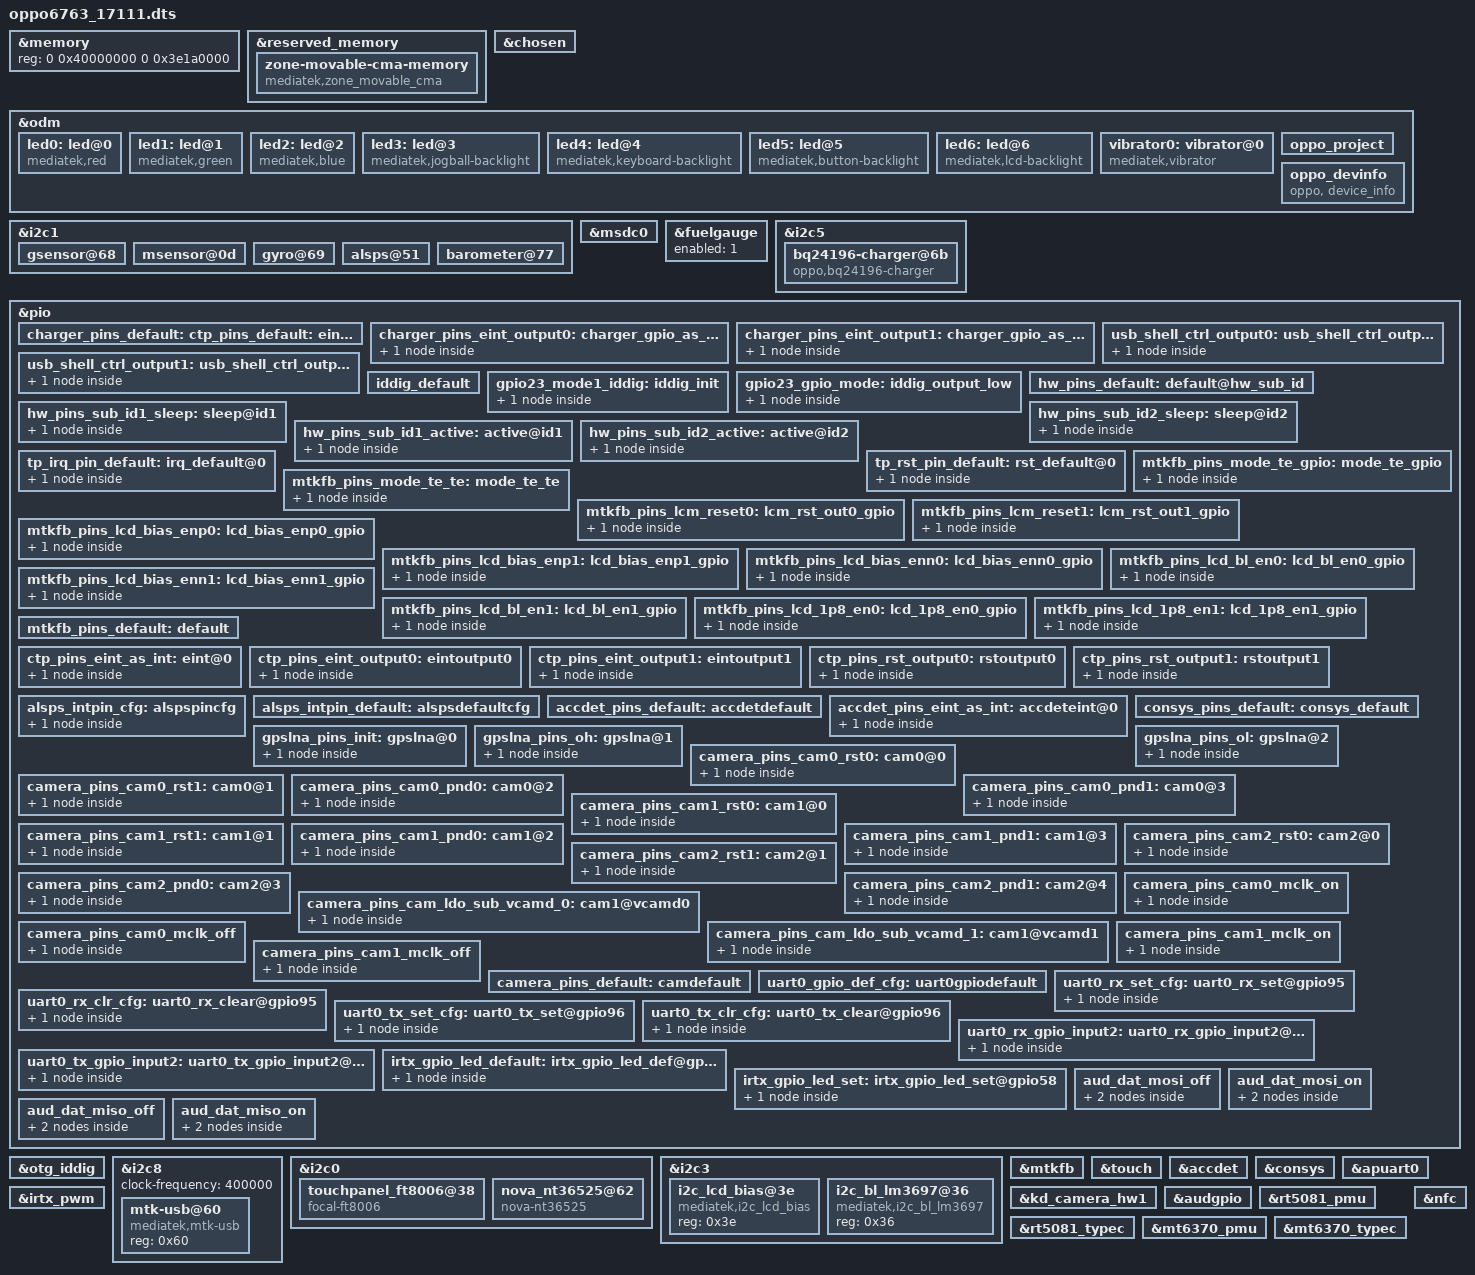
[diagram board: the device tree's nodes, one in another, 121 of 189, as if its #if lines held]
#include <generated/autoconf.h>
/dts-v1/;

#ifdef CONFIG_MTK_DTBO_FEATURE
/plugin/;
#include <dt-bindings/interrupt-controller/irq.h>
#include <dt-bindings/interrupt-controller/arm-gic.h>
#include <dt-bindings/mmc/mt6763-msdc.h>
#include <dt-bindings/pinctrl/mt6763-pinfunc.h>
#else
#include "mt6763.dts"
#endif


&memory {
		device_type = "memory";
		reg = <0 0x40000000 0 0x3e1a0000>;
};

&reserved_memory {
		#address-cells = <2>;
		#size-cells = <2>;
		ranges;

		zone-movable-cma-memory {
			compatible = "mediatek,zone_movable_cma";
			size = <0 0xffc00000>;
			alignment = <0 0x10000000>;
			alloc-ranges = <0 0xc0000000 1 0x00000000>;
	};
};


/* chosen */
&chosen {
		bootargs = "console=tty0 console=ttyMT0,921600n1 root=/dev/ram initrd=0x45000000,\
0x1000000 loglevel=8 androidboot.selinux=permissive androidboot.hardware=mt6763 initcall_debug=1 maxcpus=1";
		/* fpga may has no lk, we need to specify display info here */
		/* fb buffer is reserved using this dts by memory node above */
		atag,videolfb-fb_base_h = <0x0>;
		atag,videolfb-fb_base_l = <0x5e605000>;
		atag,videolfb-islcmfound = <1>;
		/* because no lk, so lcm is not inited */
		atag,videolfb-islcm_inited = <0>;
		atag,videolfb-fps= <6000>;
		atag,videolfb-vramSize= <0x017bb000>;
		atag,videolfb-lcmname= "nt35695B_fhd_dsi_cmd_auo_rt5081_drv";
};

&odm {
	led0:led@0 {
		compatible = "mediatek,red";
		led_mode = <0>;
		data = <1>;
		pwm_config = <0 0 0 0 0>;
	};
	led1:led@1 {
		compatible = "mediatek,green";
		led_mode = <0>;
		data = <1>;
		pwm_config = <0 0 0 0 0>;
	};
	led2:led@2 {
		compatible = "mediatek,blue";
		led_mode = <0>;
		data = <1>;
		pwm_config = <0 0 0 0 0>;
	};
	led3:led@3 {
		compatible = "mediatek,jogball-backlight";
		led_mode = <0>;
		data = <1>;
		pwm_config = <0 0 0 0 0>;
	};
	led4:led@4 {
		compatible = "mediatek,keyboard-backlight";
		led_mode = <0>;
		data = <1>;
		pwm_config = <0 0 0 0 0>;
	};
	led5:led@5 {
		compatible = "mediatek,button-backlight";
		led_mode = <0>;
		data = <1>;
		pwm_config = <0 0 0 0 0>;
	};
	led6:led@6 {
		compatible = "mediatek,lcd-backlight";
		/* #ifndef VENDOR_EDIT */
		/* LiPing-m@PSW.MM.Display.LCD.Machine, 2017/11/03, Add for porting 17331 lcd driver */
		/* led_mode = <5>; */
		/* #else VENDOR_EDIT */
		led_mode = <4>;
		/* #endif VENDOR_EDIT */
		data = <1>;
		pwm_config = <0 3 0 0 0>;
	};
	vibrator0:vibrator@0 {
		compatible = "mediatek,vibrator";
		vib_timer = <25>;
		vib_limit = <9>;
		vib_vol= <9>;
	};
    //#ifdef VENDOR_EDIT
	/*Bin.Li@EXP.BSP.bootloader.bootflow, 2017/05/15, Add for oppo project */
	oppo_project:oppo_project {
		nProject = <0>;
		nModem = <0>;
		nOperator = <0>;
		nPCBVersion = <0>;
	};
	//#endif /*VENDOR_EDIT*/
    //ifdef VENDOR_EDIT
	/* Bin.Li@EXP.BSP.bootloader.bootflow, 2017/07/07, Add device-info */
	oppo_devinfo:oppo_devinfo {
			compatible = "oppo, device_info";
		};
	//endif
};

&i2c1 {
/*  start sensor */
	gsensor@68 {
		i2c_num	= <1>;
		direction = <4>;
		power_id = <0xffff>;
		power_vol = <0>;
		firlen = <16>;
		is_batch_supported = <1>;
	};

	msensor@0d {
		i2c_num = <1>;
		i2c_addr = <0x0d 0 0 0>;
		direction = <8>;
		power_id = <0xffff>;
		power_vol = <0>;
		is_batch_supported = <0>;
	};

	gyro@69 {
		i2c_num = <1>;
		i2c_addr = <0x69 0 0 0>;
		direction = <4>;
		power_id = <0xffff>;
		power_vol = <0>;
		firlen = <0>;
		is_batch_supported = <0>;
	};

	alsps@51 {
		pinctrl-names = "pin_default", "pin_cfg";
		pinctrl-0 = <&alsps_intpin_default>;
		pinctrl-1 = <&alsps_intpin_cfg>;
		status = "okay";
		/* customization */
		i2c_num = <1>;
		i2c_addr = <0x51 0 0 0>;
		polling_mode_ps = <0>;
		polling_mode_als = <1>;
		power_id = <0xffff>;
		power_vol = <0>;
		als_level = <0 328 861 1377 3125 7721 7767 12621 23062 28430 33274 47116 57694 57694 65535>;
		als_value = <0 133 304 502 1004 2005 3058 5005 8008 10010 12000 16000 20000 20000 20000 20000>;
		ps_threshold_high = <26>;
		ps_threshold_low = <21>;
		is_batch_supported_ps = <0>;
		is_batch_supported_als = <0>;
	};

	barometer@77 {
		i2c_num = <1>;
		i2c_addr = <0x77 0 0 0>;
		direction = <0>;
		power_id = <0xffff>;
		power_vol = <0>;
		firlen = <32>;
		is_batch_supported = <0>;
	};
/* end sensor */
};

&msdc0 {
	status = "okay";
};
//#ifdef VENDOR_EDIT
//PengNan@BSP.CHG.Basic, 2017/09/07, add for compatabling two fuelgauge.
&fuelgauge{
	enabled = <1>;
};
//#endif
//#ifdef VENDOR_EDIT
/* ChaoYing.Chen@EXP.BSP.CHG.basic, 2017/05/31, Add for charge driver */
&i2c5 {
	bq24196-charger@6b {
		status = "okay";
		compatible = "oppo,bq24196-charger";
		reg = <0x6b 0>;
		pinctrl-names = "default", "charger_gpio_as_output_low", "charger_gpio_as_output_high", "usb_shell_ctrl_output_low", "usb_shell_ctrl_output_high";
		pinctrl-0 = <&charger_pins_default>;
		pinctrl-1 = <&charger_pins_eint_output0>;
		pinctrl-2 = <&charger_pins_eint_output1>;
		pinctrl-3 = <&usb_shell_ctrl_output0>;
		pinctrl-4 = <&usb_shell_ctrl_output1>;
		qcom,input_current_charger_ma = <2000>;
		qcom,input_current_usb_ma = <500>;
		qcom,input_current_led_ma = <900>;
		qcom,input_current_led_ma_forcmcc = <500>;
		qcom,input_current_camera_ma = <1200>;

		qcom,input_current_calling_ma = <1500>;
		qcom,iterm-disabled = <0>;
		qcom,iterm-ma = <150>;
		qcom,recharge-mv = <100>;
		qcom,external_gauge;
		qcom,batt_capacity_mah = <3090>;
		qcom,removed_bat_decidegc = <190>;  /* < -19C */
		qcom,cold_bat_decidegc = <30>;  /* -3C ~ 0C */
		qcom,temp_cold_vfloat_mv = <3980>;
		qcom,temp_cold_fastchg_current_ma = <364>;
		qcom,little_cold_bat_decidegc = <0>;	/* 0C ~ 5C */
		qcom,temp_little_cold_vfloat_mv = <4370>;
		qcom,temp_little_cold_fastchg_current_ma = <435>;
		qcom,cool_bat_decidegc = <50>;	/* 5C ~ 12C */
		qcom,temp_cool_vfloat_mv = <4370>;
		qcom,temp_cool_fastchg_current_ma_high = <725>;
		qcom,temp_cool_fastchg_current_ma_low = <435>;
		qcom,little_cool_bat_decidegc = <120>;	/* 12C ~ 22C */
		qcom,temp_little_cool_vfloat_mv = <4370>;
		qcom,temp_little_cool_fastchg_current_ma = <1380>;
		qcom,normal_bat_decidegc = <220>;	/* 22C ~ 45C */
		qcom,temp_normal_fastchg_current_ma = <2024>;
		qcom,temp_normal_vfloat_mv_normalchg = <4370>;
		qcom,temp_normal_vfloat_mv_voocchg = <4370>;
		qcom,warm_bat_decidegc = <450>;		/* 45C ~ 53C */
		qcom,temp_warm_vfloat_mv = <4080>;
		qcom,temp_warm_fastchg_current_ma = <725>;
		qcom,hot_bat_decidegc = <530>;
		qcom,non_standard_vfloat_mv = <4000>;
		qcom,non_standard_fastchg_current_ma = <512>;
		qcom,non_standard_vfloat_sw_limit = <3950>;
		qcom,cold_vfloat_sw_limit = <3930>;
		qcom,little_cold_vfloat_sw_limit = <4320>;
		qcom,cool_vfloat_sw_limit = <4320>;
		qcom,little_cool_vfloat_sw_limit = <4320>;
		qcom,normal_vfloat_sw_limit = <4320>;
		qcom,warm_vfloat_sw_limit = <4030>;

		qcom,non_standard_vfloat_over_sw_limit = <3980>;
		qcom,cold_vfloat_over_sw_limit = <3980>;
		qcom,little_cold_vfloat_over_sw_limit = <4390>;
		qcom,cool_vfloat_over_sw_limit = <4390>;
		qcom,little_cool_vfloat_over_sw_limit = <4390>;
		qcom,normal_vfloat_over_sw_limit = <4390>;
		qcom,warm_vfloat_over_sw_limit = <4080>;
		qcom,sw_vfloat_over_protect_enable;

		qcom,max_chg_time_sec = <36000>;
		qcom,charger_hv_thr = <5800>;
		qcom,charger_lv_thr = <3400>;
		qcom,vbatt_full_thr = <4400>;
		qcom,vbatt_hv_thr = <4500>;
		qcom,vfloat_step_mv = <16>;
	//	qcom,suspend_after_full;
		qcom,check_batt_full_by_sw;
		qcom,chg_ctrl_by_calling;
		qcom,chg_ctrl_by_lcd;
		qcom,chg_ctrl_by_camera;
		qcom,usb_shell_ctrl;
		qcom,usb_switch_gpio 		= <&pio 3 0x00>;
		qcom,usb_shell_ctrl_gpio 			= <&pio 21 0x00>;
	};
};

&pio {
	charger_pins_default: eint0default {
	};
	charger_pins_eint_output0: charger_gpio_as_output_low {
		pins_cmd_dat {
			pins = <PINMUX_GPIO3__FUNC_GPIO3>;
			slew-rate = <1>;
			output-low;
		};
	};
	charger_pins_eint_output1: charger_gpio_as_output_high {
		pins_cmd_dat {
			pins = <PINMUX_GPIO3__FUNC_GPIO3>;
			slew-rate = <1>;
			output-high;
		};
	};
	usb_shell_ctrl_output0: usb_shell_ctrl_output_low {
		pins_cmd_dat {
			pins = <PINMUX_GPIO21__FUNC_GPIO21>;
			slew-rate = <1>;
			output-low;	
		};
	};
	usb_shell_ctrl_output1: usb_shell_ctrl_output_high {
		pins_cmd_dat {
			pins = <PINMUX_GPIO21__FUNC_GPIO21>;
			slew-rate = <1>;
			output-high;	
		};
	};
};
&otg_iddig {
	/* Qiao.Hu@EXP.BSP.CHG.basic, 2017/05/09, Add for otg support */
	pinctrl-names = "iddig_default", "iddig_init", "iddig_output_low" ;
	pinctrl-0 = <&iddig_default>;
	pinctrl-1 = <&gpio23_mode1_iddig>;
	pinctrl-2 = <&gpio23_gpio_mode>;
	status = "okay";
    	/* Qiao.Hu@EXP.BSP.CHG.basic, 2017/05/25, Add for OTG GPIO */
	qcom,otg_switch_gpio = <23>;

};
&pio {
	iddig_default: iddig_default {
	};

	gpio23_mode1_iddig: iddig_init {
		pins_cmd_dat {
			pins = <PINMUX_GPIO23__FUNC_IDDIG>;
			slew-rate = <0>;
			bias-pull-up = <00>;
		};
	};
	gpio23_gpio_mode: iddig_output_low {
		pins_cmd_dat {
			pins = <PINMUX_GPIO23__FUNC_GPIO23>;
			slew-rate = <1>;
			output-low;
		};
	};

};
//#endif /* VENDOR_EDIT */

//ifdef VENDOR_EDIT
/* Bin.Li@EXP.BSP.bootloader.bootflow, 2017/07/07, Add device-info */
&oppo_devinfo {
	Hw,sub_hwid_1 = <&pio 10 0x00>;
	Hw,sub_hwid_2 = <&pio 58 0x00>;
	pinctrl-names = "default", "hw_sub_id_sleep", "hw_sub_id_active";
	pinctrl-0 = <&hw_pins_sub_id1_active &hw_pins_sub_id2_active>;
	pinctrl-1 = <&hw_pins_sub_id1_sleep &hw_pins_sub_id2_sleep>;
	pinctrl-2 = <&hw_pins_sub_id1_active &hw_pins_sub_id2_active>;
};

&pio {
	hw_pins_default:default@hw_sub_id {
	};

	hw_pins_sub_id1_sleep:sleep@id1 {
			pins_cmd_dat {
			pins = <PINMUX_GPIO10__FUNC_GPIO10>;
			slew-rate = <0>;
			bias-pull-down = <00>;
			input-enable;
			};
	};

	hw_pins_sub_id2_sleep:sleep@id2 {
			pins_cmd_dat {
			pins = <PINMUX_GPIO58__FUNC_GPIO58>;
			bias-pull-down = <00>;
			input-enable;
			};
	};

	hw_pins_sub_id1_active:active@id1 {
		pins_cmd_dat {
		pins = <PINMUX_GPIO10__FUNC_GPIO10>;
			slew-rate = <0>;
			bias-pull-up = <00>;
			input-enable;
			};
	};
	hw_pins_sub_id2_active:active@id2 {
		pins_cmd_dat {
		pins = <PINMUX_GPIO58__FUNC_GPIO58>;
			slew-rate = <0>;
			bias-pull-up = <00>;
			input-enable;
			};
	};
};
//endif

&i2c8 {
	#address-cells = <1>;
	#size-cells = <0>;
	clock-frequency = <400000>;

	mtk-usb@60 {
		compatible = "mediatek,mtk-usb";
		reg = <0x60>;
		status = "okay";
	};
};

//#ifdef VENDOR_EDIT
/* ZhongWenjie@PSW.BSP.TP,  2018/05/07, Add for TP ft8006*/
&i2c0 {
    touchpanel_ft8006@38 {
        compatible = "focal-ft8006";
        reg = <0x38>;
        status = "okay";
        chip-name = "FT8006";

        interrupt-parent = <&eintc>;
        interrupts = <1 0x2002>;

        irq-gpio = <&pio 1 0x2002>;
        reset-gpio = <&pio 7 0>;

        pinctrl-names = "default";
        pinctrl-0 = <&tp_irq_pin_default &tp_rst_pin_default>;

        touchpanel,max-num-support = <10>;
        touchpanel,tx-rx-num = <18 32>;
        touchpanel,panel-coords = <720 1440>;
        touchpanel,display-coords = <720 1440>;

        incell_screen;
        edge_limit_support;
        charger_pump_support;
        black_gesture_support;
        esd_handle_support;
        //spurious_fingerprint_support;
        //lcd_trigger_fp_check;
        black_gesture_test_support;

        /*
        *Virtual Key Config:
        *1:touchpanel,button-type: <virtualkey_type  supportted_button-map>
        *virtualkey_type:
        *Type 1: using board_properties
        *Type 2: using same IC (button zone&& touch zone are seprate)
        *Type 3: using diffrent IC (button zone&& touch zone are seprate)
        *Type 4: No need of virtual key process
        *supportted_button-map:select|menu|home|back
        *
        *2:touchpanel,button-map
        *type (X1,Y1)(X2,Y2)(X3,Y3)(Width_X,Hight_Y)--Only when button-type is 0
        */

        touchpanel,button-type = <4 0x00>;
    };

    nova_nt36525@62 {
        compatible = "nova-nt36525";
        reg = <0x62>;
        status = "okay";
        chip-name = "NT36525";

        interrupt-parent = <&eintc>;
        interrupts = <1 0x2001>;
        irq-gpio = <&pio 1 0x2001>;

        pinctrl-names = "default";
        pinctrl-0 = <&tp_irq_pin_default &tp_rst_pin_default>;

        touchpanel,max-num-support = <10>;
        touchpanel,tx-rx-num = <18 32>;
        touchpanel,panel-coords = <720 1440>;
        touchpanel,display-coords = <720 1440>;

        incell_screen;
        edge_limit_support;
        black_gesture_support;
        charger_pump_support;
        esd_handle_support;
        //spurious_fingerprint_support;
        //lcd_trigger_fp_check;
        black_gesture_test_support;

        /*
        *Virtual Key Config:
        *1:touchpanel,button-type: <virtualkey_type  supportted_button-map>
        *virtualkey_type:
        *Type 1: using board_properties
        *Type 2: using same IC (button zone&& touch zone are seprate)
        *Type 3: using diffrent IC (button zone&& touch zone are seprate)
        *Type 4: No need of virtual key process
        *supportted_button-map:select|menu|home|back
        *
        *2:touchpanel,button-map
        *type (X1,Y1)(X2,Y2)(X3,Y3)(Width_X,Hight_Y)--Only when button-type is 0
        */

        touchpanel,button-type = <2 0x05>;
    };
};

&pio {
    tp_irq_pin_default:irq_default@0 {
        pins_cmd_dat {
            pins = <PINMUX_GPIO1__FUNC_GPIO1>;
            slew-rate = <0>;
            bias-pull-up;
            input-enable;
        };
    };

    tp_rst_pin_default:rst_default@0 {
        pins_cmd_dat {
            pins = <PINMUX_GPIO7__FUNC_GPIO7>;
            slew-rate = <1>;
            bias-disable;
        };
    };
};
//#endif /* VENDOR_EDIT */

/* #ifdef VENDOR_EDIT */
/* LiPing-m@PSW.MM.Display.LCD.Machine, 2017/11/03, Add for porting 17331 lcd driver */
&i2c3 {
    #address-cells = <1>;
    #size-cells = <0>;

       i2c_lcd_bias@3e {
               compatible = "mediatek,i2c_lcd_bias";
               reg = <0x3e>;
               status = "okay";
       };
       i2c_bl_lm3697@36 {
               compatible = "mediatek,i2c_bl_lm3697";
               reg = <0x36>;
               status = "okay";
       };
};

&pio {

	mtkfb_pins_mode_te_gpio: mode_te_gpio {
		pins_cmd_dat {
			pins = <PINMUX_GPIO44__FUNC_GPIO44>;
	};
		};

	mtkfb_pins_mode_te_te: mode_te_te {
		pins_cmd_dat {
			pins = <PINMUX_GPIO44__FUNC_DSI_TE>;
		};
};

	mtkfb_pins_lcm_reset0: lcm_rst_out0_gpio {
		pins_cmd_dat {
			pins = <PINMUX_GPIO45__FUNC_GPIO45>;
			slew-rate = <1>;
			output-low;
		};
};

	mtkfb_pins_lcm_reset1: lcm_rst_out1_gpio {
		pins_cmd_dat {
			pins = <PINMUX_GPIO45__FUNC_GPIO45>;
			slew-rate = <1>;
			output-high;
		};
};

	mtkfb_pins_lcd_bias_enp0: lcd_bias_enp0_gpio {
		pins_cmd_dat {
			pins = <PINMUX_GPIO23__FUNC_GPIO23>;
			slew-rate = <1>;
			output-low;
		};
};

	mtkfb_pins_lcd_bias_enp1: lcd_bias_enp1_gpio {
		pins_cmd_dat {
			pins = <PINMUX_GPIO23__FUNC_GPIO23>;
			slew-rate = <1>;
			output-high;
		};
	};

	mtkfb_pins_lcd_bias_enn0: lcd_bias_enn0_gpio {
		pins_cmd_dat {
			pins = <PINMUX_GPIO24__FUNC_GPIO24>;
			slew-rate = <1>;
			output-low;
		};
	};

	mtkfb_pins_lcd_bias_enn1: lcd_bias_enn1_gpio {
		pins_cmd_dat {
			pins = <PINMUX_GPIO24__FUNC_GPIO24>;
			slew-rate = <1>;
			output-high;
		};
	};

	mtkfb_pins_lcd_bl_en0: lcd_bl_en0_gpio {
		pins_cmd_dat {
			pins = <PINMUX_GPIO66__FUNC_GPIO66>;
			slew-rate = <1>;
			output-low;
		};
	};

	mtkfb_pins_lcd_bl_en1: lcd_bl_en1_gpio {
		pins_cmd_dat {
			pins = <PINMUX_GPIO66__FUNC_GPIO66>;
			slew-rate = <1>;
			output-high;
		};
	};

	mtkfb_pins_lcd_1p8_en0: lcd_1p8_en0_gpio {
		pins_cmd_dat {
			pins = <PINMUX_GPIO65__FUNC_GPIO65>;
			slew-rate = <1>;
			output-low;
		};
	};

	mtkfb_pins_lcd_1p8_en1: lcd_1p8_en1_gpio {
		pins_cmd_dat {
			pins = <PINMUX_GPIO65__FUNC_GPIO65>;
			slew-rate = <1>;
			output-high;
		};
	};

	mtkfb_pins_default: default {
};
};

&mtkfb {
	pinctrl-names = "default", "mode_te_gpio", "mode_te_te", "lcm_rst_out0_gpio",
	"lcm_rst_out1_gpio", "lcd_bias_enp0_gpio", "lcd_bias_enp1_gpio",
	"lcd_bias_enn0_gpio","lcd_bias_enn1_gpio","lcd_bl_en0_gpio",
	"lcd_bl_en1_gpio","lcd_1p8_en0_gpio","lcd_1p8_en1_gpio";
	pinctrl-0 = <&mtkfb_pins_default>;
	pinctrl-1 = <&mtkfb_pins_mode_te_gpio>;
	pinctrl-2 = <&mtkfb_pins_mode_te_te>;
	pinctrl-3 = <&mtkfb_pins_lcm_reset0>;
	pinctrl-4 = <&mtkfb_pins_lcm_reset1>;
	pinctrl-5 = <&mtkfb_pins_lcd_bias_enp0>;
	pinctrl-6 = <&mtkfb_pins_lcd_bias_enp1>;
	pinctrl-7 = <&mtkfb_pins_lcd_bias_enn0>;
	pinctrl-8 = <&mtkfb_pins_lcd_bias_enn1>;
	pinctrl-9 = <&mtkfb_pins_lcd_bl_en0>;
	pinctrl-10 = <&mtkfb_pins_lcd_bl_en1>;
	pinctrl-11 = <&mtkfb_pins_lcd_1p8_en0>;
	pinctrl-12 = <&mtkfb_pins_lcd_1p8_en1>;
	status = "okay";
};
/* #endif VENDOR_EDIT */

/* TOUCH start */
&touch {
	tpd-resolution = <1080 1920>;
	use-tpd-button = <0>;
	tpd-key-num = <3>;
	tpd-key-local= <139 172 158 0>;
	tpd-key-dim-local = <90 883 100 40 230 883 100 40 370 883 100 40 0 0 0 0>;
	tpd-max-touch-num = <5>;
	tpd-filter-enable = <1>;
	tpd-filter-pixel-density = <146>;
	tpd-filter-custom-prameters = <0 0 0 0 0 0 0 0 0 0 0 0>;
	tpd-filter-custom-speed = <0 0 0>;
	pinctrl-names = "default", "state_eint_as_int", "state_eint_output0", "state_eint_output1",
		"state_rst_output0", "state_rst_output1";
	pinctrl-0 = <&ctp_pins_default>;
	pinctrl-1 = <&ctp_pins_eint_as_int>;
	pinctrl-2 = <&ctp_pins_eint_output0>;
	pinctrl-3 = <&ctp_pins_eint_output1>;
	pinctrl-4 = <&ctp_pins_rst_output0>;
	pinctrl-5 = <&ctp_pins_rst_output1>;
	status = "okay";
};
&pio {
	ctp_pins_default: eint0default {
	};
	ctp_pins_eint_as_int: eint@0 {
		pins_cmd_dat {
			pins = <PINMUX_GPIO1__FUNC_GPIO1>;
			slew-rate = <0>;
			bias-disable;
		};
	};
	ctp_pins_eint_output0: eintoutput0 {
		pins_cmd_dat {
			pins = <PINMUX_GPIO1__FUNC_GPIO1>;
			slew-rate = <1>;
			output-low;
		};
	};
	ctp_pins_eint_output1: eintoutput1 {
		pins_cmd_dat {
			pins = <PINMUX_GPIO1__FUNC_GPIO1>;
			slew-rate = <1>;
			output-high;
		};
	};
	ctp_pins_rst_output0: rstoutput0 {
		pins_cmd_dat {
			pins = <PINMUX_GPIO10__FUNC_GPIO10>;
			slew-rate = <1>;
			output-low;
		};
	};
	ctp_pins_rst_output1: rstoutput1 {
		pins_cmd_dat {
			pins = <PINMUX_GPIO10__FUNC_GPIO10>;
			slew-rate = <1>;
			output-high;
		};
	};
};
/* TOUCH end */

/* sensor gpio standization */
&pio {
	alsps_intpin_cfg: alspspincfg {

		pins_cmd_dat {
			pins = <PINMUX_GPIO6__FUNC_GPIO6>;
			slew-rate = <0>;
			bias-pull-up = <00>;
		};
	};

	alsps_intpin_default: alspsdefaultcfg {

	};
};
/* sensor end */

/* accdet start */
&accdet {
	/* accdet micbias voltage: 0x07,2.7v;0x05,2.5v;0x02,1.9v */
	//#ifdef VENDOR_EDIT
	//xiang.fei@PSW.MM.AudioDriver.Codec, 2018/06/06,
	//modify for changing micbias vol to 2.7V for headset mic
	accdet-mic-vol = <7>;
	//#else /* VENDOR_EDIT */
	//accdet-mic-vol = <6>;
	//#endif /* VENDOR_EDIT */
	headset-mode-setting = <0x500 0x500 1 0x1f0 0x800 0x800 0x20 0x44>;
	accdet-plugout-debounce = <1>;
	/*1:ACC mode, 2:low cost without in bias, 6:low cost with in bias*/
	//#ifdef VENDOR_EDIT
	//xiang.fei@PSW.MM.AudioDriver.HeadsetDet, 2018/06/06, Modify for ACC MODE
	accdet-mic-mode = <1>;
	//#else /* VENDOR_EDIT */
	//accdet-mic-mode = <2>;
	//#endif /* VENDOR_EDIT */
	/* eint_level_trigger: 8,LEVEL_LOW(default);4,LEVEL_HIGH;others,LEVEL_LOW */
	headset-eint-level-pol = <8>;
	/*0--MD_MAX--UP_MAX--DW_MAX*/
	//#ifdef VENDOR_EDIT
	//xiang.fei@PSW.MM.AudioDriver.HeadsetDet, 2018/06/06, Modify for support headset key
	headset-three-key-threshold = <0 82 170 306>;
	//#else /* VENDOR_EDIT */
	//headset-three-key-threshold = <0 80 220 400>;
	//#endif /* VENDOR_EDIT */
	headset-three-key-threshold-CDD = <0 121 192 600>;
	/*0--MD_MAX--VOICE_MAX--UP_MAX--DW_MAX*/
	headset-four-key-threshold = <0 58 121 192 400>;
	/* ACCDET GPIO standardization ACC mode no use */
	pinctrl-names = "default", "state_eint_as_int";
	pinctrl-0 = <&accdet_pins_default>;
	pinctrl-1 = <&accdet_pins_eint_as_int>;
	status = "okay";
};
&pio {
	accdet_pins_default: accdetdefault {
	};
	accdet_pins_eint_as_int: accdeteint@0 {
		pins_cmd_dat {
			pins = <PINMUX_GPIO9__FUNC_GPIO9>;
			slew-rate = <0>;
			bias-disable;
		};
	};
};
/* accdet end */

/* CONSYS GPIO standardization */
&pio {
	consys_pins_default: consys_default {
	};
	gpslna_pins_init: gpslna@0 {
		pins_cmd_dat {
			pins = <PINMUX_GPIO107__FUNC_GPIO107>;
			slew-rate = <0>;
			bias-disable;
			output-low;
		};
	};
	gpslna_pins_oh: gpslna@1 {
		pins_cmd_dat {
			pins = <PINMUX_GPIO107__FUNC_GPIO107>;
			slew-rate = <1>;
			output-high;
		};
	};
	gpslna_pins_ol: gpslna@2 {
		pins_cmd_dat {
			pins = <PINMUX_GPIO107__FUNC_GPIO107>;
			slew-rate = <1>;
			output-low;
		};
	};
};
&consys {
	pinctrl-names = "default", "gps_lna_state_init", "gps_lna_state_oh", "gps_lna_state_ol";
	pinctrl-0 = <&consys_pins_default>;
	pinctrl-1 = <&gpslna_pins_init>;
	pinctrl-2 = <&gpslna_pins_oh>;
	pinctrl-3 = <&gpslna_pins_ol>;
	status = "okay";
};
/* CONSYS end */

 /* CAMERA GPIO standardization */
&pio {
	camera_pins_cam0_rst0: cam0@0 {
		pins_cmd_dat {
			pins = <PINMUX_GPIO101__FUNC_GPIO101>;
			slew-rate = <1>; /*direction 0:in, 1:out*/
			output-low;/*direction out used only. output_low or high*/
		};
	};
	camera_pins_cam0_rst1: cam0@1 {
		pins_cmd_dat {
			pins = <PINMUX_GPIO101__FUNC_GPIO101>;
			slew-rate = <1>;
			output-high;
		};
	};
	camera_pins_cam0_pnd0: cam0@2 {
		pins_cmd_dat {
			pins = <PINMUX_GPIO97__FUNC_GPIO97>;
			slew-rate = <1>;
			output-low;
		};
	};
	camera_pins_cam0_pnd1: cam0@3 {
		pins_cmd_dat {
			pins = <PINMUX_GPIO97__FUNC_GPIO97>;
			slew-rate = <1>;
			output-high;
		};
	};
	camera_pins_cam1_rst0: cam1@0 {
		pins_cmd_dat {
			pins = <PINMUX_GPIO102__FUNC_GPIO102>;
			slew-rate = <1>; /*direction 0:in, 1:out*/
			output-low;/*direction out used only. output_low or high*/
		};
	};
	camera_pins_cam1_rst1: cam1@1 {
		pins_cmd_dat {
			pins = <PINMUX_GPIO102__FUNC_GPIO102>;
			slew-rate = <1>;
			output-high;
		};
	};
	camera_pins_cam1_pnd0: cam1@2 {
		pins_cmd_dat {
			pins = <PINMUX_GPIO98__FUNC_GPIO98>;
			slew-rate = <1>;
			output-low;
		};
	};
	camera_pins_cam1_pnd1: cam1@3 {
		pins_cmd_dat {
			pins = <PINMUX_GPIO98__FUNC_GPIO98>;
			slew-rate = <1>;
			output-high;
		};
	};
	camera_pins_cam2_rst0: cam2@0 {
		pins_cmd_dat {
			pins = <PINMUX_GPIO86__FUNC_GPIO86>;
			slew-rate = <1>;
			output-low;
		};
	};
	camera_pins_cam2_rst1: cam2@1 {
		pins_cmd_dat {
			pins = <PINMUX_GPIO86__FUNC_GPIO86>;
			slew-rate = <1>;
			output-high;
		};
	};
	camera_pins_cam2_pnd0: cam2@3 {
		pins_cmd_dat {
			pins = <PINMUX_GPIO85__FUNC_GPIO85>;
			slew-rate = <1>;
			output-low;
		};
	};
	camera_pins_cam2_pnd1: cam2@4 {
		pins_cmd_dat {
			pins = <PINMUX_GPIO85__FUNC_GPIO85>;
			slew-rate = <1>;
			output-high;
		};
	};
	camera_pins_cam_ldo_sub_vcamd_0: cam1@vcamd0 {
		pins_cmd_dat {
			pins = <PINMUX_GPIO17__FUNC_GPIO17>;
			slew-rate = <1>;
			output-low;
		};
	};
	camera_pins_cam_ldo_sub_vcamd_1: cam1@vcamd1 {
		pins_cmd_dat {
			pins = <PINMUX_GPIO17__FUNC_GPIO17>;
			slew-rate = <1>;
			output-high;
		};
	};
	camera_pins_cam0_mclk_on: camera_pins_cam0_mclk_on {
		pins_cmd_dat {
			pins = <PINMUX_GPIO99__FUNC_CMMCLK0>;
		};
	};
	camera_pins_cam0_mclk_off: camera_pins_cam0_mclk_off {
		pins_cmd_dat {
			pins = <PINMUX_GPIO99__FUNC_GPIO99>;
		};
	};
	camera_pins_cam1_mclk_on: camera_pins_cam1_mclk_on {
		pins_cmd_dat {
			pins = <PINMUX_GPIO100__FUNC_CMMCLK1>;
		};
	};
	camera_pins_cam1_mclk_off: camera_pins_cam1_mclk_off {
		pins_cmd_dat {
			pins = <PINMUX_GPIO100__FUNC_GPIO100>;
		};
	};
	camera_pins_default: camdefault {
	};

};

&kd_camera_hw1 {
	pinctrl-names = "default",
			"cam0_rst0", "cam0_rst1", "cam0_pnd0", "cam0_pnd1",
			"cam1_rst0", "cam1_rst1", "cam1_pnd0", "cam1_pnd1",
			"cam2_rst0", "cam2_rst1", "cam2_pnd0", "cam2_pnd1",
			"cam_ldo_sub_vcamd_0", "cam_ldo_sub_vcamd_1",
			"cam0_mclk_on", "cam0_mclk_off",
			"cam1_mclk_on", "cam1_mclk_off";

	pinctrl-0 = <&camera_pins_default>;
	pinctrl-1 = <&camera_pins_cam0_rst0>;
	pinctrl-2 = <&camera_pins_cam0_rst1>;
	pinctrl-3 = <&camera_pins_cam0_pnd0>;
	pinctrl-4 = <&camera_pins_cam0_pnd1>;
	pinctrl-5 = <&camera_pins_cam1_rst0>;
	pinctrl-6 = <&camera_pins_cam1_rst1>;
	pinctrl-7 = <&camera_pins_cam1_pnd0>;
	pinctrl-8 = <&camera_pins_cam1_pnd1>;
	pinctrl-9 = <&camera_pins_cam2_rst0>;
	pinctrl-10 = <&camera_pins_cam2_rst1>;
	pinctrl-11 = <&camera_pins_cam2_pnd0>;
	pinctrl-12 = <&camera_pins_cam2_pnd1>;
	pinctrl-13 = <&camera_pins_cam_ldo_sub_vcamd_0>;
	pinctrl-14 = <&camera_pins_cam_ldo_sub_vcamd_1>;
	pinctrl-15 = <&camera_pins_cam0_mclk_on>;
	pinctrl-16 = <&camera_pins_cam0_mclk_off>;
	pinctrl-17 = <&camera_pins_cam1_mclk_on>;
	pinctrl-18 = <&camera_pins_cam1_mclk_off>;
	status = "okay";

};
/* CAMERA GPIO end */

/* UART GPIO */
&apuart0 {
	pinctrl-names = "uart0_gpio_default",
			"uart0_rx_set",
			"uart0_rx_clear",
			"uart0_tx_set",
			"uart0_tx_clear",
//#ifdef VENDOR_EDIT
//PengNan@BSP.CHG.Basic, 2017/08/10, add for switch uart mode for chargerid.
			"uart0_rx_gpio",
			"uart0_tx_gpio";
//#endif /*VENDOR_EDIT*/
	pinctrl-0 = <&uart0_gpio_def_cfg>;
	pinctrl-1 = <&uart0_rx_set_cfg>;
	pinctrl-2 = <&uart0_rx_clr_cfg>;
	pinctrl-3 = <&uart0_tx_set_cfg>;
	pinctrl-4 = <&uart0_tx_clr_cfg>;
//#ifdef VENDOR_EDIT
//PengNan@BSP.CHG.Basic, 2017/08/10, add for switch uart mode for chargerid.
	pinctrl-5 = <&uart0_rx_gpio_input2>;
	pinctrl-6 = <&uart0_tx_gpio_input2>;
//#endif /*VENDOR_EDIT*/
	status = "okay";
};

&pio {
	/* UART GPIO Settings - Start */
	/* UART0: rx set, rx clear, tx clear, tx clear*/
	uart0_gpio_def_cfg:uart0gpiodefault {

	};
	uart0_rx_set_cfg:uart0_rx_set@gpio95 {
		pins_cmd_dat {
			pins = <PINMUX_GPIO95__FUNC_URXD0>;
		};
	};
	uart0_rx_clr_cfg:uart0_rx_clear@gpio95 {
		pins_cmd_dat {
			pins = <PINMUX_GPIO95__FUNC_GPIO95>;
			slew-rate = <1>;
			output-high;
		};
	};
	uart0_tx_set_cfg:uart0_tx_set@gpio96 {
		pins_cmd_dat {
			pins = <PINMUX_GPIO96__FUNC_UTXD0>;
		};
	};
	uart0_tx_clr_cfg:uart0_tx_clear@gpio96 {
		pins_cmd_dat {
			pins = <PINMUX_GPIO96__FUNC_GPIO96>;
			slew-rate = <1>;
			output-high;
		};
	};
//#ifdef VENDOR_EDIT
//PengNan@BSP.CHG.Basic, 2017/08/10, add for switch uart mode for chargerid.
	uart0_rx_gpio_input2:uart0_rx_gpio_input2@gpio95 {
		pins_cmd_dat {
			pins = <PINMUX_GPIO95__FUNC_GPIO95>;
			input-enable;
			slew-rate = <0>;
			bias-disable;
		};
	};
	uart0_tx_gpio_input2:uart0_tx_gpio_input2@gpio96 {
		pins_cmd_dat {
			pins = <PINMUX_GPIO96__FUNC_GPIO96>;
			input-enable;
			slew-rate = <0>;
			bias-disable;
		};
	};
//#endif /*VENDOR_EDIT*/
};/* UART GPIO end */

/* IRTX GPIO end */
&irtx_pwm {
	pinctrl-names = "irtx_gpio_led_default", "irtx_gpio_led_set";
	pinctrl-0 = <&irtx_gpio_led_default>;
	pinctrl-1 = <&irtx_gpio_led_set>;
	status = "okay";
};
&pio {
	/* IRTX GPIO Settings -Start */
	/* default: GPIO0, output, high */
	irtx_gpio_led_default:irtx_gpio_led_def@gpio58 {
		pins_cmd_dat {
			pins = <PINMUX_GPIO58__FUNC_GPIO58>;
			slew-rate = <1>;
			bias-disable;
			output-low;
			input-schmitt-enable = <0>;
		};
	};

	irtx_gpio_led_set:irtx_gpio_led_set@gpio58 {
		pins_cmd_dat {
			pins = <PINMUX_GPIO58__FUNC_PWM_B>;
			slew-rate = <1>;
			output-high;
		};
	};
}; /* IRTX GPIO Settings -End */

/* AUDIO GPIO standardization */
&audgpio {
	pinctrl-names = "aud_dat_mosi_off",
			"aud_dat_mosi_on",
			"aud_dat_miso_off",
			"aud_dat_miso_on";
	pinctrl-0 = <&aud_dat_mosi_off>;
	pinctrl-1 = <&aud_dat_mosi_on>;
	pinctrl-2 = <&aud_dat_miso_off>;
	pinctrl-3 = <&aud_dat_miso_on>;
	status = "okay";
};

&pio {
	aud_dat_mosi_off: aud_dat_mosi_off {
		pins_cmd1_dat {
			pins = <PINMUX_GPIO138__FUNC_GPIO138>;
			input-enable;
			slew-rate = <0>;
			bias-disable;
		};
		pins_cmd2_dat {
			pins = <PINMUX_GPIO139__FUNC_GPIO139>;
			input-enable;
			slew-rate = <0>;
			bias-disable;
		};
	};

	aud_dat_mosi_on: aud_dat_mosi_on {
		pins_cmd1_dat {
			pins = <PINMUX_GPIO138__FUNC_AUD_DAT_MOSI0>;
		};
		pins_cmd2_dat {
			pins = <PINMUX_GPIO139__FUNC_AUD_DAT_MOSI1>;
		};
	};

	aud_dat_miso_off: aud_dat_miso_off {
		pins_cmd1_dat {
			pins = <PINMUX_GPIO142__FUNC_GPIO142>;
			input-enable;
			slew-rate = <0>;
			bias-disable;
		};
		pins_cmd2_dat {
			pins = <PINMUX_GPIO143__FUNC_GPIO143>;
			input-enable;
			slew-rate = <0>;
			bias-disable;
		};
	};

	aud_dat_miso_on: aud_dat_miso_on {
		pins_cmd1_dat {
			pins = <PINMUX_GPIO142__FUNC_AUD_DAT_MISO0>;
		};
		pins_cmd2_dat {
			pins = <PINMUX_GPIO143__FUNC_AUD_DAT_MISO1>;
		};
	};
};
/* AUDIO end */

#ifdef CONFIG_MFD_RT5081_PMU
&rt5081_pmu {
	rt,intr_gpio_num = <91>; /* direct defined GPIO num */
	rt,intr_gpio = <&pio 91 0x0>;
};
#endif
#ifdef CONFIG_TCPC_RT5081
&rt5081_typec {
	rt5081pd,intr_gpio_num = <41>; /* direct defined GPIO num */
	rt5081pd,intr_gpio = <&pio 41 0x0>;
};
#endif
#ifdef CONFIG_MFD_MT6370_PMU
&mt6370_pmu {
	mt6370,intr_gpio_num = <91>; /* direct defined GPIO num */
	mt6370,intr_gpio = <&pio 91 0x0>;
};
#endif
#ifdef CONFIG_TCPC_MT6370
&mt6370_typec {
	mt6370pd,intr_gpio_num = <41>; /* direct defined GPIO num */
	mt6370pd,intr_gpio = <&pio 41 0x0>;
};
#endif


&nfc {
	gpio-rst = <21>;
	gpio-rst-std = <&pio 21 0x0>;
	gpio-irq = <22>;
	gpio-irq-std = <&pio 22  0x0>;
};

&mtkfb {
	partial-update = <1>;
	status = "okay";
};

#include <oppo6763_17111/cust.dtsi>
/*End of this file, DO NOT ADD ANYTHING HERE*/
